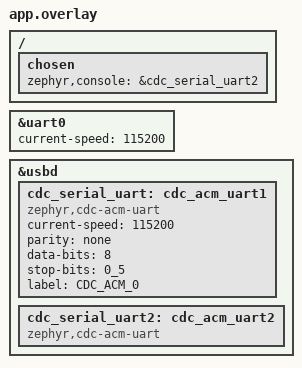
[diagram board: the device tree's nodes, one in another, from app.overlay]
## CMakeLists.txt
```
#
# Copyright (c) 2022 Nordic Semiconductor ASA
#
# SPDX-License-Identifier: LicenseRef-Nordic-5-Clause
#

cmake_minimum_required(VERSION 3.20.5)
cmake_policy(SET CMP0057 NEW)

find_package(Zephyr REQUIRED HINTS $ENV{ZEPHYR_BASE})

add_compile_options(-Wno-unused-function -Wno-unused-variable)


list(APPEND CMAKE_MODULE_PATH ${ZEPHYR_BASE}/modules/nanopb)
include(nanopb)

project(embedded80211_serial)

target_include_directories(app PUBLIC ${ZEPHYR_BASE}/subsys/net/ip)

set(PROTO_DIR ${CMAKE_CURRENT_SOURCE_DIR}/protos)
set(PROTO_FILES ${PROTO_DIR}/wifi.proto)

# Generate C sources from .proto files
# The function will create targets for generating the .pb.c and .pb.h files.
zephyr_nanopb_sources(app ${PROTO_DIR}/wifi.proto)

# we need to be able to include generated protobuf header files
zephyr_library_include_directories(${CMAKE_CURRENT_BINARY_DIR})

target_include_directories(app PUBLIC src)


target_sources(app PRIVATE
	src/main.c
	src/wifi_mgmt_proxy.c
)

add_subdirectory(src/serial)
```

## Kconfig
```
#
# Copyright (c) 2022 Nordic Semiconductor
#
# SPDX-License-Identifier: LicenseRef-Nordic-5-Clause
#

source "Kconfig.zephyr"

menu "Nordic Sta sample"

config CONNECTION_IDLE_TIMEOUT
	int "Time to be waited for a station to connect"
	default 30

config NRF70_QSPI_ENCRYPTION_KEY
	string "16 bytes QSPI encryption key, only for testing purposes"
	depends on BOARD_NRF7002DK_NRF5340_CPUAPP
	help
	  Specify the QSPI encryption key

config STA_CONN_TIMEOUT_SEC
	int "Overall Connection timeout i.e., time to be waited for a station to connect and get an IP address"
	# Zephyr DHCP retry is 1 minute, so set the default to 70 seconds
	default 70
	# 512 has no special meaning, just a reasonable upper limit
	range 0 512
	help
	  Specify the connection timeout, in seconds. This is the overall timeout i.e., time to be waited for
	  a station to connect and get an IP address. DHCP retries should be taken into account when setting
	  this value. If the timeout is set to 0, the connection will not timeout.

config STA_SAMPLE_START_WIFI_THREAD_STACK_SIZE
	int "Stack size for Wi-Fi start thread"
	default 4096
	help
	  Set the stack size for the Wi-Fi start thread.
endmenu

rsource "src/serial/Kconfig"
```

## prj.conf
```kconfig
#
# Copyright (c) 2025 Mikko Jaakkola
#
#
CONFIG_WIFI=y
CONFIG_WIFI_NRF70=y

# WPA supplicant
CONFIG_WIFI_NM_WPA_SUPPLICANT=y
CONFIG_WIFI_READY_LIB=y
CONFIG_NRF_WIFI_RPU_RECOVERY=y

CONFIG_WIFI_CREDENTIALS=y
CONFIG_WIFI_CREDENTIALS_STATIC=y
CONFIG_WIFI_CREDENTIALS_STATIC_SSID="Myssid"
CONFIG_WIFI_CREDENTIALS_STATIC_PASSWORD="Mypassword"

# Networking
CONFIG_NETWORKING=y
CONFIG_NET_SOCKETS=y
CONFIG_NET_LOG=y
CONFIG_NET_IPV4=y
CONFIG_NET_UDP=y
CONFIG_NET_TCP=y
CONFIG_NET_DHCPV4=y

CONFIG_NET_PKT_RX_COUNT=16
CONFIG_NET_PKT_TX_COUNT=16
CONFIG_NRF70_RX_NUM_BUFS=16

# Below section is the primary contributor to SRAM and is currently
# tuned for performance, but this will be revisited in the future.
CONFIG_NET_BUF_RX_COUNT=16
CONFIG_NET_BUF_TX_COUNT=32
CONFIG_HEAP_MEM_POOL_SIZE=37000
CONFIG_HEAP_MEM_POOL_IGNORE_MIN=y
CONFIG_NRF_WIFI_CTRL_HEAP_SIZE=20000
CONFIG_NRF_WIFI_DATA_HEAP_SIZE=40000
CONFIG_NET_TC_TX_COUNT=1

CONFIG_NET_IF_UNICAST_IPV4_ADDR_COUNT=1
CONFIG_NET_MAX_CONTEXTS=5
CONFIG_NET_CONTEXT_SYNC_RECV=y

CONFIG_INIT_STACKS=y

CONFIG_NET_L2_ETHERNET=y

CONFIG_NET_CONFIG_SETTINGS=y
CONFIG_NET_CONFIG_INIT_TIMEOUT=0

CONFIG_NET_SOCKETS_POLL_MAX=10

# Memories
CONFIG_MAIN_STACK_SIZE=5200
CONFIG_NET_TX_STACK_SIZE=4096
CONFIG_NET_RX_STACK_SIZE=4096
CONFIG_STA_SAMPLE_START_WIFI_THREAD_STACK_SIZE=5200

# Debugging
CONFIG_STACK_SENTINEL=y
CONFIG_DEBUG_COREDUMP=y
CONFIG_DEBUG_COREDUMP_BACKEND_LOGGING=y
CONFIG_DEBUG_COREDUMP_MEMORY_DUMP_MIN=y
CONFIG_SHELL_CMDS_RESIZE=n


# Kernel options
CONFIG_ENTROPY_GENERATOR=y

# Logging
CONFIG_LOG=y
CONFIG_LOG_BUFFER_SIZE=2048
CONFIG_POSIX_CLOCK=y

CONFIG_NET_CONFIG_MY_IPV4_ADDR="192.168.1.99"
CONFIG_NET_CONFIG_MY_IPV4_NETMASK="255.255.255.0"
CONFIG_NET_CONFIG_MY_IPV4_GW="192.168.1.1"

# printing of scan results puts pressure on queues in new locking
# design in net_mgmt. So, use a higher timeout for a crowded
# environment.
CONFIG_NET_MGMT_EVENT_QUEUE_TIMEOUT=5000

# Nanopb
CONFIG_NANOPB=y

# Enable USB Subsystem
CONFIG_USB_DEVICE_STACK=y
CONFIG_USB_DEVICE_PRODUCT="My Zephyr CDC-ACM Device"
 # Temporary USB VID/PID for testing
CONFIG_USB_DEVICE_PID=0x0001

# Enable CDC ACM Class
CONFIG_USB_CDC_ACM=y

# Serial
CONFIG_SERIAL=y
 # Needed for USB CDC ACM. Aysynchronous serial port
# API would be better for all other serial ports.
CONFIG_UART_INTERRUPT_DRIVEN=y

# Enable RTT (Real-Time Transfer)
CONFIG_RTT_CONSOLE=y

# Choose SEGGER RTT as the backend (most common)
CONFIG_USE_SEGGER_RTT=y
CONFIG_SEGGER_RTT_BUFFER_SIZE_UP=1024
CONFIG_SEGGER_RTT_BUFFER_SIZE_DOWN=64

CONFIG_UART_CONSOLE=y

# Workqueue
CONFIG_SYSTEM_WORKQUEUE_STACK_SIZE=2048
CONFIG_SYSTEM_WORKQUEUE_PRIORITY=4

# Enable events
CONFIG_EVENTS=y
```

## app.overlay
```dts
&uart0 {
    status = "okay";
    current-speed = <115200>; // Set baud rate
};


zephyr_udc0: &usbd {
    status = "okay";
    cdc_serial_uart: cdc_acm_uart1 { // This creates an instance named "CDC_ACM_0"
        compatible = "zephyr,cdc-acm-uart";
		current-speed = <115200>;
		parity = "none";
		data-bits = <8>;
		stop-bits = "0_5";
        label = "CDC_ACM_0";
        status = "okay";
    };
    cdc_serial_uart2: cdc_acm_uart2 { // This creates an instance named "CDC_ACM_1"
        compatible = "zephyr,cdc-acm-uart";
    };
};

/ {
     chosen {
         zephyr,console = &cdc_serial_uart2;
     };
};
```

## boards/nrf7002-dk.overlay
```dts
/ {
    chosen {
        zephyr,shell-uart = &uart0; // If you want it for shell too
        zephyr,console = &uart0;   // If you want it for console
        my-serial-port = &uart0; // A custom alias for your app
    };
};

&zephyr_udc0 {
    status = "okay";
    cdc_acm_uart0 { // This creates an instance named "CDC_ACM_0"
        compatible = "zephyr,cdc-acm-uart";
        label = "CDC_ACM_0";
    };
};


&uart0 {
    status = "okay";
    current-speed = <115200>; // Set baud rate
};
```

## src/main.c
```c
/*
 * Copyright (c) 2022 Nordic Semiconductor ASA
 *
 * SPDX-License-Identifier: LicenseRef-Nordic-5-Clause
 */

/** @file
 * @brief WiFi station sample
 */

#include <zephyr/logging/log.h>
LOG_MODULE_REGISTER(embedded80211_serial, CONFIG_LOG_DEFAULT_LEVEL);

#include <zephyr/kernel.h>
#include <stdio.h>
#include <stdlib.h>
#include <zephyr/shell/shell.h>
#include <zephyr/sys/printk.h>
#include <zephyr/init.h>

#include <zephyr/net/net_if.h>
#include <zephyr/net/wifi_mgmt.h>
#include <zephyr/net/net_event.h>
#include <zephyr/drivers/gpio.h>

#ifdef CONFIG_WIFI_READY_LIB
#include <net/wifi_ready.h>
#endif /* CONFIG_WIFI_READY_LIB */

#if defined(CONFIG_BOARD_NRF7002DK_NRF7001_NRF5340_CPUAPP) || \
	defined(CONFIG_BOARD_NRF7002DK_NRF5340_CPUAPP)
#include <zephyr/drivers/wifi/nrf_wifi/bus/qspi_if.h>
#endif

#include "net_private.h"

#define WIFI_SHELL_MODULE "wifi"

#define WIFI_SHELL_MGMT_EVENTS (NET_EVENT_WIFI_CONNECT_RESULT |		\
				NET_EVENT_WIFI_DISCONNECT_RESULT)

#define MAX_SSID_LEN        32
#define STATUS_POLLING_MS   300

/* 1000 msec = 1 sec */
#define LED_SLEEP_TIME_MS   100

/* The devicetree node identifier for the "led0" alias. */
#define LED0_NODE DT_ALIAS(led0)
/*
 * A build error on this line means your board is unsupported.
 * See the sample documentation for information on how to fix this.
 */
static const struct gpio_dt_spec led = GPIO_DT_SPEC_GET(LED0_NODE, gpios);

static struct net_mgmt_event_callback wifi_shell_mgmt_cb;
static struct net_mgmt_event_callback net_shell_mgmt_cb;

#ifdef CONFIG_WIFI_READY_LIB
static K_SEM_DEFINE(wifi_ready_state_changed_sem, 0, 1);
static bool wifi_ready_status;
#endif /* CONFIG_WIFI_READY_LIB */

static struct {
	const struct shell *sh;
	union {
		struct {
			uint8_t connected	: 1;
			uint8_t connect_result	: 1;
			uint8_t disconnect_requested	: 1;
			uint8_t _unused		: 5;
		};
		uint8_t all;
	};
} context;

void toggle_led(void)
{
	int ret;

	if (!device_is_ready(led.port)) {
		LOG_ERR("LED device is not ready");
		return;
	}

	ret = gpio_pin_configure_dt(&led, GPIO_OUTPUT_ACTIVE);
	if (ret < 0) {
		LOG_ERR("Error %d: failed to configure LED pin", ret);
		return;
	}

	while (1) {
		if (context.connected) {
			gpio_pin_toggle_dt(&led);
			k_msleep(LED_SLEEP_TIME_MS);
		} else {
			gpio_pin_set_dt(&led, 0);
			k_msleep(LED_SLEEP_TIME_MS);
		}
	}
}

K_THREAD_DEFINE(led_thread_id, 1024, toggle_led, NULL, NULL, NULL,
		7, 0, 0);

static int cmd_wifi_status(void)
{
	struct net_if *iface = net_if_get_default();
	struct wifi_iface_status status = { 0 };

	if (net_mgmt(NET_REQUEST_WIFI_IFACE_STATUS, iface, &status,
				sizeof(struct wifi_iface_status))) {
		LOG_INF("Status request failed");

		return -ENOEXEC;
	}

	LOG_INF("==================");
	LOG_INF("State: %s", wifi_state_txt(status.state));

	if (status.state >= WIFI_STATE_ASSOCIATED) {
		uint8_t mac_string_buf[sizeof("xx:xx:xx:xx:xx:xx")];

		LOG_INF("Interface Mode: %s",
		       wifi_mode_txt(status.iface_mode));
		LOG_INF("Link Mode: %s",
		       wifi_link_mode_txt(status.link_mode));
		LOG_INF("SSID: %.32s", status.ssid);
		LOG_INF("BSSID: %s",
		       net_sprint_ll_addr_buf(
				status.bssid, WIFI_MAC_ADDR_LEN,
				mac_string_buf, sizeof(mac_string_buf)));
		LOG_INF("Band: %s", wifi_band_txt(status.band));
		LOG_INF("Channel: %d", status.channel);
		LOG_INF("Security: %s", wifi_security_txt(status.security));
		LOG_INF("MFP: %s", wifi_mfp_txt(status.mfp));
		LOG_INF("RSSI: %d", status.rssi);
	}
	return 0;
}

static void handle_wifi_connect_result(struct net_mgmt_event_callback *cb)
{
	const struct wifi_status *status =
		(const struct wifi_status *) cb->info;

	if (context.connected) {
		return;
	}

	if (status->status) {
		LOG_ERR("Connection failed (%d)", status->status);
	} else {
		LOG_INF("Connected");
		context.connected = true;
	}

	context.connect_result = true;
}

static void handle_wifi_disconnect_result(struct net_mgmt_event_callback *cb)
{
	const struct wifi_status *status =
		(const struct wifi_status *) cb->info;

	if (!context.connected) {
		return;
	}

	if (context.disconnect_requested) {
		LOG_INF("Disconnection request %s (%d)",
			 status->status ? "failed" : "done",
					status->status);
		context.disconnect_requested = false;
	} else {
		LOG_INF("Received Disconnected");
		context.connected = false;
	}

	cmd_wifi_status();
}

static void wifi_mgmt_event_handler(struct net_mgmt_event_callback *cb,
				     uint32_t mgmt_event, struct net_if *iface)
{
	switch (mgmt_event) {
	case NET_EVENT_WIFI_CONNECT_RESULT:
		handle_wifi_connect_result(cb);
		break;
	case NET_EVENT_WIFI_DISCONNECT_RESULT:
		handle_wifi_disconnect_result(cb);
		break;
	default:
		break;
	}
}

static void print_dhcp_ip(struct net_mgmt_event_callback *cb)
{
	/* Get DHCP info from struct net_if_dhcpv4 and print */
	const struct net_if_dhcpv4 *dhcpv4 = cb->info;
	const struct in_addr *addr = &dhcpv4->requested_ip;
	char dhcp_info[128];

	net_addr_ntop(AF_INET, addr, dhcp_info, sizeof(dhcp_info));

	LOG_INF("DHCP IP address: %s", dhcp_info);
}
static void net_mgmt_event_handler(struct net_mgmt_event_callback *cb,
				    uint32_t mgmt_event, struct net_if *iface)
{
	switch (mgmt_event) {
	case NET_EVENT_IPV4_DHCP_BOUND:
		print_dhcp_ip(cb);
		break;
	default:
		break;
	}
}

static int wifi_connect(void)
{
	struct net_if *iface = net_if_get_first_wifi();

	context.connected = false;
	context.connect_result = false;

	if (net_mgmt(NET_REQUEST_WIFI_CONNECT_STORED, iface, NULL, 0)) {
		LOG_ERR("Connection request failed");

		return -ENOEXEC;
	}

	LOG_INF("Connection requested");

	return 0;
}

int bytes_from_str(const char *str, uint8_t *bytes, size_t bytes_len)
{
	size_t i;
	char byte_str[3];

	if (strlen(str) != bytes_len * 2) {
		LOG_ERR("Invalid string length: %zu (expected: %d)\n",
			strlen(str), bytes_len * 2);
		return -EINVAL;
	}

	for (i = 0; i < bytes_len; i++) {
		memcpy(byte_str, str + i * 2, 2);
		byte_str[2] = '\0';
		bytes[i] = strtol(byte_str, NULL, 16);
	}

	return 0;
}

int start_app(void)
{
#if defined(CONFIG_BOARD_NRF7002DK_NRF7001_NRF5340_CPUAPP) || \
	defined(CONFIG_BOARD_NRF7002DK_NRF5340_CPUAPP)
	if (strlen(CONFIG_NRF70_QSPI_ENCRYPTION_KEY)) {
		int ret;
		char key[QSPI_KEY_LEN_BYTES];

		ret = bytes_from_str(CONFIG_NRF70_QSPI_ENCRYPTION_KEY, key, sizeof(key));
		if (ret) {
			LOG_ERR("Failed to parse encryption key: %d\n", ret);
			return 0;
		}

		LOG_DBG("QSPI Encryption key: ");
		for (int i = 0; i < QSPI_KEY_LEN_BYTES; i++) {
			LOG_DBG("%02x", key[i]);
		}
		LOG_DBG("\n");

		ret = qspi_enable_encryption(key);
		if (ret) {
			LOG_ERR("Failed to enable encryption: %d\n", ret);
			return 0;
		}
		LOG_INF("QSPI Encryption enabled");
	} else {
		LOG_INF("QSPI Encryption disabled");
	}
#endif /* CONFIG_BOARD_NRF700XDK_NRF5340 */

	LOG_INF("Static IP address (overridable): %s/%s -> %s",
		CONFIG_NET_CONFIG_MY_IPV4_ADDR,
		CONFIG_NET_CONFIG_MY_IPV4_NETMASK,
		CONFIG_NET_CONFIG_MY_IPV4_GW);

	while (1) {
#ifdef CONFIG_WIFI_READY_LIB
		int ret;

		LOG_INF("Waiting for Wi-Fi to be ready");
		ret = k_sem_take(&wifi_ready_state_changed_sem, K_FOREVER);
		if (ret) {
			LOG_ERR("Failed to take semaphore: %d", ret);
			return ret;
		}

check_wifi_ready:
		if (!wifi_ready_status) {
			LOG_INF("Wi-Fi is not ready");
			/* Perform any cleanup and stop using Wi-Fi and wait for
			 * Wi-Fi to be ready
			 */
			continue;
		}
#endif /* CONFIG_WIFI_READY_LIB */
		wifi_connect();

		while (!context.connect_result) {
			cmd_wifi_status();
			k_sleep(K_MSEC(STATUS_POLLING_MS));
		}

		if (context.connected) {
			cmd_wifi_status();
#ifdef CONFIG_WIFI_READY_LIB
			ret = k_sem_take(&wifi_ready_state_changed_sem, K_FOREVER);
			if (ret) {
				LOG_ERR("Failed to take semaphore: %d", ret);
				return ret;
			}
			goto check_wifi_ready;
#else
			k_sleep(K_FOREVER);
#endif /* CONFIG_WIFI_READY_LIB */
		}
	}

	return 0;
}

#ifdef CONFIG_WIFI_READY_LIB
void start_wifi_thread(void);
#define THREAD_PRIORITY K_PRIO_COOP(CONFIG_NUM_COOP_PRIORITIES - 1)
K_THREAD_DEFINE(start_wifi_thread_id, CONFIG_STA_SAMPLE_START_WIFI_THREAD_STACK_SIZE,
		start_wifi_thread, NULL, NULL, NULL,
		THREAD_PRIORITY, 0, -1);

void start_wifi_thread(void)
{
	start_app();
}

void wifi_ready_cb(bool wifi_ready)
{
	LOG_DBG("Is Wi-Fi ready?: %s", wifi_ready ? "yes" : "no");
	wifi_ready_status = wifi_ready;
	k_sem_give(&wifi_ready_state_changed_sem);
}
#endif /* CONFIG_WIFI_READY_LIB */

void net_mgmt_callback_init(void)
{
	memset(&context, 0, sizeof(context));

	net_mgmt_init_event_callback(&wifi_shell_mgmt_cb,
				     wifi_mgmt_event_handler,
				     WIFI_SHELL_MGMT_EVENTS);

	net_mgmt_add_event_callback(&wifi_shell_mgmt_cb);

	net_mgmt_init_event_callback(&net_shell_mgmt_cb,
				     net_mgmt_event_handler,
				     NET_EVENT_IPV4_DHCP_BOUND);

	net_mgmt_add_event_callback(&net_shell_mgmt_cb);

	LOG_INF("Starting %s with CPU frequency: %d MHz", CONFIG_BOARD, SystemCoreClock/MHZ(1));
	k_sleep(K_SECONDS(1));
}

#ifdef CONFIG_WIFI_READY_LIB
static int register_wifi_ready(void)
{
	int ret = 0;
	wifi_ready_callback_t cb;
	struct net_if *iface = net_if_get_first_wifi();

	if (!iface) {
		LOG_ERR("Failed to get Wi-Fi interface");
		return -1;
	}

	cb.wifi_ready_cb = wifi_ready_cb;

	LOG_DBG("Registering Wi-Fi ready callbacks");
	ret = register_wifi_ready_callback(cb, iface);
	if (ret) {
		LOG_ERR("Failed to register Wi-Fi ready callbacks %s", strerror(ret));
		return ret;
	}

	return ret;
}
#endif /* CONFIG_WIFI_READY_LIB */

int main(void)
{
	int ret = 0;

	int counter = 12;

	while(counter--) {
		LOG_INF("Starting %s with CPU frequency: %d MHz", CONFIG_BOARD, SystemCoreClock/MHZ(1));
		k_sleep(K_SECONDS(1));
	}

	net_mgmt_callback_init();

#ifdef CONFIG_WIFI_READY_LIB
	ret = register_wifi_ready();
	if (ret) {
		return ret;
	}
	k_thread_start(start_wifi_thread_id);
#else
	start_app();
#endif /* CONFIG_WIFI_READY_LIB */
	return ret;
}
```

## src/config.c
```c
#include "serial/serial.h"
#include "wifi_mgmt_proxy.h"
#include "wifi_data.h"

struct client_callbacks client_cb[SERIAL_TYPE_UNKNOWN] = {
    [SERIAL_TYPE_WIFI_MGMT] = {
        .acquire_buffer = wifi_mgmt_acquire_buffer, // Set to your buffer acquisition function
        .commit_data = wifi_mgmt_commit_data, // Set to your commit data function
        .message_complete = wifi_mgmt_message_complete, // Set to your message complete function
    },
    [SERIAL_TYPE_WIFI_DATA] = {
        .acquire_buffer = wifi_data_acquire_buffer,
        .commit_data = wifi_data_commit_data,
        .message_complete = wifi_data_message_complete,
    },
    [SERIAL_TYPE_HCI] = {
        .acquire_buffer = NULL,
        .commit_data = NULL,
        .message_complete = NULL,
    },
    [SERIAL_TYPE_THREAD] = {
        .acquire_buffer = NULL,
        .commit_data = NULL,
        .message_complete = NULL,
    },
    [SERIAL_TYPE_AT_CMD] = {
        .acquire_buffer = NULL,
        .commit_data = NULL,
        .message_complete = NULL,
    },
};
```

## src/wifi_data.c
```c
#include <zephyr/kernel.h>
#include <zephyr/logging/log.h>
#include <zephyr/net/net_if.h>
#include <zephyr/net/net_pkt.h>
#include <zephyr/net/wifi_mgmt.h>

#include "wifi_data.h"

LOG_MODULE_REGISTER(wifi_data, LOG_LEVEL_INF);

#define WIFI_MGMT_EVENTS (NET_EVENT_WIFI_CONNECT_RESULT |		\
				NET_EVENT_WIFI_DISCONNECT_RESULT | \
                NET_EVENT_WIFI_AP_STA_DISCONNECTED | \
                NET_EVENT_WIFI_AP_STA_CONNECTED | \
            	NET_EVENT_WIFI_CMD_DISCONNECT_COMPLETE)

static struct net_if_dev* wifi_dev;
static struct net_mgmt_event_callback wifi_mgmt_cb;
static size_t message_length;
static uint8_t wifi_data_tx_buffer[1600];


static void wifi_mgmt_event_handler(struct net_mgmt_event_callback *cb,
				     uint32_t mgmt_event, struct net_if *iface)
{
	switch (mgmt_event) {
	case NET_EVENT_WIFI_CONNECT_RESULT:
		// Open data gates
		break;
	case NET_EVENT_WIFI_DISCONNECT_RESULT:
		// Stop data transmission
		break;
    case NET_EVENT_WIFI_AP_STA_DISCONNECTED:
        LOG_INF("A station disconnected from the AP");
        break;
    case NET_EVENT_WIFI_AP_STA_CONNECTED:
        LOG_INF("A station connected to the AP");
        break;
    case NET_EVENT_WIFI_CMD_DISCONNECT_COMPLETE:
        LOG_INF("Wi-Fi disconnect command completed");
        // Handle disconnect completion, e.g., reset state or notify user
        break;
	default:
        LOG_WRN("Unhandled Wi-Fi management event: %u", mgmt_event);
		break;
	}
}

static void wifi_iface_enumeration_cb(struct net_if *iface, void *user_data)
{
    if (net_if_is_wifi(iface)) {
        LOG_INF("Found Wi-Fi interface: %p", iface);
        // store only the first one - implement later how to narrow is down to a specific device.
        // multi-device support comes even later.

        if (wifi_dev == NULL) {
            wifi_dev = iface->if_dev;
            LOG_INF("Storing Wi-Fi device: %p", wifi_dev);

            /* Register link layer status callback for this interface */
            net_mgmt_init_event_callback(&wifi_mgmt_cb, wifi_mgmt_event_handler, WIFI_MGMT_EVENTS);
        	net_mgmt_add_event_callback(&wifi_mgmt_cb);
        } else {
            LOG_WRN("Multiple Wi-Fi interfaces found, only the first will be used.");
        }
    }
}

bool wifi_data_acquire_buffer(uint8_t **data, size_t len)
{
    // Check if the ring buffer has enough space
    if (len > (sizeof(wifi_data_tx_buffer) - message_length)) {
        LOG_WRN("Not enough space in buffer for %zu bytes, Abort", len);
        // TODO: This is severe error condition and should happen. Reseting things would be an appropriate action.
        return false;
    }
    return true; // Indicate that the buffer is available
}


void wifi_data_commit_data(size_t len)
{
    message_length += len; // Update the total message length
}

void wifi_data_message_complete(size_t len)
{
    struct net_if *iface = net_if_lookup_by_dev(wifi_dev->dev);
    if (iface == NULL) {
        LOG_ERR("Failed to get network interface for Wi-Fi device");
        return;
    }

    struct net_pkt *pkt = net_pkt_alloc_with_buffer(iface, len, AF_UNSPEC, 0, K_FOREVER);

    if (pkt == NULL) {
        LOG_ERR("Failed to acquire packet & buffer of size %zu", len);
    }

    message_length += len; // Update the total message length

    net_pkt_write(pkt, &wifi_data_tx_buffer[4], message_length);

    message_length = 0; // Reset after sending

    if (net_send_data(pkt) < 0) {
        LOG_ERR("Failed to send Wi-Fi data packet");
        net_pkt_unref(pkt);
    }
}



static int init_wifi_data()
{
    net_if_foreach(wifi_iface_enumeration_cb, NULL);

    return 0;
}

SYS_INIT(init_wifi_data, APPLICATION, CONFIG_APPLICATION_INIT_PRIORITY);
```

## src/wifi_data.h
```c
#ifndef _WIFI_DATA_H_
#define _WIFI_DATA_H_

bool wifi_data_acquire_buffer(uint8_t **data, size_t len);
void wifi_data_commit_data(size_t len);
void wifi_data_message_complete(size_t len);


#endif // _WIFI_DATA_H_
```

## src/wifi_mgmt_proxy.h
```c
#ifndef _WIFI_MGMT_PROXY_H_
#define _WIFI_MGMT_PROXY_H_

#include <serial/serial.h>

bool wifi_mgmt_acquire_buffer(uint8_t **data, size_t len);
void wifi_mgmt_commit_data(size_t len);
void wifi_mgmt_message_complete(size_t len);


#if defined(CONFIG_WIFI_MGMT_BEARER_SERIAL_UART) || defined(CONFIG_WIFI_MGMT_BEARER_SERIAL_USB)
#define WIFI_MGMT_TX serial_data_tx
#else
#error "Unsupported configuration"
#endif // WIFI_MGMT_TX serial_usb_tx



#endif   // _WIFI_MGMT_PROXY_H_
```
